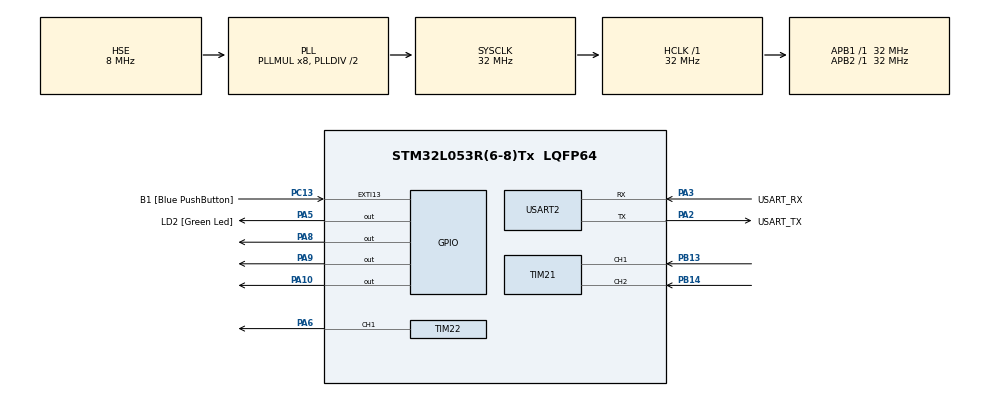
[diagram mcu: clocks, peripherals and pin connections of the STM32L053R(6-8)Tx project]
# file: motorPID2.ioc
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Mcu.Family=STM32L0
Mcu.Name=STM32L053R(6-8)Tx
Mcu.Package=LQFP64
NVIC.TIM2_IRQn=true\:0\:0\:false\:false\:true\:true\:true\:true
NVIC.USART2_IRQn=true\:0\:0\:false\:false\:true\:true\:true\:true
PA10.Signal=GPIO_Output
PA13.GPIO_Label=TMS
PA13.Mode=Serial_Wire
PA13.Signal=SYS_SWDIO
PA14.GPIO_Label=TCK
PA14.Mode=Serial_Wire
PA14.Signal=SYS_SWCLK
PA2.GPIO_Label=USART_TX
PA2.Mode=Asynchronous
PA2.Signal=USART2_TX
PA3.GPIO_Label=USART_RX
PA3.Mode=Asynchronous
PA3.Signal=USART2_RX
PA5.GPIO_Label=LD2 [Green Led]
PA5.Signal=GPIO_Output
PA6.Signal=S_TIM22_CH1
PA8.Signal=GPIO_Output
PA9.Signal=GPIO_Output
PB13.Signal=S_TIM21_CH1
PB14.Signal=S_TIM21_CH2
PC13.GPIO_Label=B1 [Blue PushButton]
PC13.GPIO_ModeDefaultEXTI=GPIO_MODE_IT_FALLING
PC13.Signal=GPXTI13
PC14-OSC32_IN.Mode=LSE-External-Oscillator
PC14-OSC32_IN.Signal=RCC_OSC32_IN
PC15-OSC32_OUT.Mode=LSE-External-Oscillator
PC15-OSC32_OUT.Signal=RCC_OSC32_OUT
PH0-OSC_IN.Mode=HSE-External-Clock-Source
PH0-OSC_IN.Signal=RCC_OSC_IN
PH1-OSC_OUT.Signal=RCC_OSC_OUT
ProjectManager.HeapSize=0x200
ProjectManager.StackSize=0x400
ProjectManager.TargetToolchain=STM32CubeIDE
RCC.AHBFreq_Value=32000000
RCC.APB1Freq_Value=32000000
RCC.APB1TimFreq_Value=32000000
RCC.APB2Freq_Value=32000000
RCC.APB2TimFreq_Value=32000000
RCC.HCLKFreq_Value=32000000
RCC.HSE_VALUE=8000000
RCC.HSI16_VALUE=16000000
RCC.HSI48_VALUE=48000000
RCC.HSI_VALUE=16000000
RCC.MSI_VALUE=2097000
RCC.PLLMUL=RCC_PLLMUL_8
RCC.PLLSourceVirtual=RCC_PLLSOURCE_HSE
RCC.SYSCLKFreq_VALUE=32000000
RCC.SYSCLKSource=RCC_SYSCLKSOURCE_PLLCLK
RCC.VCOOutputFreq_Value=64000000
SH.S_TIM21_CH1.0=TIM21_CH1,Encoder_Interface
SH.S_TIM21_CH2.0=TIM21_CH2,Encoder_Interface
SH.S_TIM22_CH1.0=TIM22_CH1,PWM Generation1 CH1
TIM2.Period=9
TIM2.Prescaler=3199
TIM21.AutoReloadPreload=TIM_AUTORELOAD_PRELOAD_ENABLE
TIM21.EncoderMode=TIM_ENCODERMODE_TI12
TIM21.IC1Filter=10
TIM22.Channel-PWM\ Generation1\ CH1=TIM_CHANNEL_1
TIM22.Period=799
USART2.VirtualMode-Asynchronous=VM_ASYNC
VP_TIM22_VS_ClockSourceINT.Mode=Internal
VP_TIM2_VS_ClockSourceINT.Mode=Internal
board=NUCLEO-L053R8

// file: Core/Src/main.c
/* USER CODE BEGIN Header */
/**
  ******************************************************************************
  * @file           : main.c
  * @brief          : Main program body
  ******************************************************************************
  * @attention
  *
  * Copyright (c) 2025 STMicroelectronics.
  * All rights reserved.
  *
  * This software is licensed under terms that can be found in the LICENSE file
  * in the root directory of this software component.
  * If no LICENSE file comes with this software, it is provided AS-IS.
  *
  ******************************************************************************
  */
/* USER CODE END Header */
#include "main.h"

/* USER CODE BEGIN Includes */
#include "myMain.h"
/* USER CODE END Includes */

TIM_HandleTypeDef htim2;
TIM_HandleTypeDef htim21;
TIM_HandleTypeDef htim22;

UART_HandleTypeDef huart2;

void SystemClock_Config(void);
static void MX_GPIO_Init(void);
static void MX_USART2_UART_Init(void);
static void MX_TIM2_Init(void);
static void MX_TIM21_Init(void);
static void MX_TIM22_Init(void);

int main(void)
{

  /* MCU Configuration--------------------------------------------------------*/

  /* Reset of all peripherals, Initializes the Flash interface and the Systick. */
  HAL_Init();

  /* Configure the system clock */
  SystemClock_Config();

  /* Initialize all configured peripherals */
  MX_GPIO_Init();
  MX_USART2_UART_Init();
  MX_TIM2_Init();
  MX_TIM21_Init();
  MX_TIM22_Init();

  /* Infinite loop */
  /* USER CODE BEGIN WHILE */

  myMain();

  while (1)
  {
    /* USER CODE END WHILE */

  }
}

void SystemClock_Config(void)
{
  RCC_OscInitTypeDef RCC_OscInitStruct = {0};
  RCC_ClkInitTypeDef RCC_ClkInitStruct = {0};
  RCC_PeriphCLKInitTypeDef PeriphClkInit = {0};

  /** Configure the main internal regulator output voltage
  */
  __HAL_PWR_VOLTAGESCALING_CONFIG(PWR_REGULATOR_VOLTAGE_SCALE1);

  /** Initializes the RCC Oscillators according to the specified parameters
  * in the RCC_OscInitTypeDef structure.
  */
  RCC_OscInitStruct.OscillatorType = RCC_OSCILLATORTYPE_HSE;
  RCC_OscInitStruct.HSEState = RCC_HSE_BYPASS;
  RCC_OscInitStruct.PLL.PLLState = RCC_PLL_ON;
  RCC_OscInitStruct.PLL.PLLSource = RCC_PLLSOURCE_HSE;
  RCC_OscInitStruct.PLL.PLLMUL = RCC_PLLMUL_8;
  RCC_OscInitStruct.PLL.PLLDIV = RCC_PLLDIV_2;
  if (HAL_RCC_OscConfig(&RCC_OscInitStruct) != HAL_OK)
  {
    Error_Handler();
  }

  /** Initializes the CPU, AHB and APB buses clocks
  */
  RCC_ClkInitStruct.ClockType = RCC_CLOCKTYPE_HCLK|RCC_CLOCKTYPE_SYSCLK
                              |RCC_CLOCKTYPE_PCLK1|RCC_CLOCKTYPE_PCLK2;
  RCC_ClkInitStruct.SYSCLKSource = RCC_SYSCLKSOURCE_PLLCLK;
  RCC_ClkInitStruct.AHBCLKDivider = RCC_SYSCLK_DIV1;
  RCC_ClkInitStruct.APB1CLKDivider = RCC_HCLK_DIV1;
  RCC_ClkInitStruct.APB2CLKDivider = RCC_HCLK_DIV1;

  if (HAL_RCC_ClockConfig(&RCC_ClkInitStruct, FLASH_LATENCY_1) != HAL_OK)
  {
    Error_Handler();
  }
  PeriphClkInit.PeriphClockSelection = RCC_PERIPHCLK_USART2;
  PeriphClkInit.Usart2ClockSelection = RCC_USART2CLKSOURCE_PCLK1;
  if (HAL_RCCEx_PeriphCLKConfig(&PeriphClkInit) != HAL_OK)
  {
    Error_Handler();
  }
}

static void MX_TIM2_Init(void)
{

  TIM_ClockConfigTypeDef sClockSourceConfig = {0};
  TIM_MasterConfigTypeDef sMasterConfig = {0};

  htim2.Instance = TIM2;
  htim2.Init.Prescaler = 3199;
  htim2.Init.CounterMode = TIM_COUNTERMODE_UP;
  htim2.Init.Period = 9;
  htim2.Init.ClockDivision = TIM_CLOCKDIVISION_DIV1;
  htim2.Init.AutoReloadPreload = TIM_AUTORELOAD_PRELOAD_DISABLE;
  if (HAL_TIM_Base_Init(&htim2) != HAL_OK)
  {
    Error_Handler();
  }
  sClockSourceConfig.ClockSource = TIM_CLOCKSOURCE_INTERNAL;
  if (HAL_TIM_ConfigClockSource(&htim2, &sClockSourceConfig) != HAL_OK)
  {
    Error_Handler();
  }
  sMasterConfig.MasterOutputTrigger = TIM_TRGO_RESET;
  sMasterConfig.MasterSlaveMode = TIM_MASTERSLAVEMODE_DISABLE;
  if (HAL_TIMEx_MasterConfigSynchronization(&htim2, &sMasterConfig) != HAL_OK)
  {
    Error_Handler();
  }

}

static void MX_TIM21_Init(void)
{

  TIM_Encoder_InitTypeDef sConfig = {0};
  TIM_MasterConfigTypeDef sMasterConfig = {0};

  htim21.Instance = TIM21;
  htim21.Init.Prescaler = 0;
  htim21.Init.CounterMode = TIM_COUNTERMODE_UP;
  htim21.Init.Period = 65535;
  htim21.Init.ClockDivision = TIM_CLOCKDIVISION_DIV1;
  htim21.Init.AutoReloadPreload = TIM_AUTORELOAD_PRELOAD_ENABLE;
  sConfig.EncoderMode = TIM_ENCODERMODE_TI12;
  sConfig.IC1Polarity = TIM_ICPOLARITY_RISING;
  sConfig.IC1Selection = TIM_ICSELECTION_DIRECTTI;
  sConfig.IC1Prescaler = TIM_ICPSC_DIV1;
  sConfig.IC1Filter = 10;
  sConfig.IC2Polarity = TIM_ICPOLARITY_RISING;
  sConfig.IC2Selection = TIM_ICSELECTION_DIRECTTI;
  sConfig.IC2Prescaler = TIM_ICPSC_DIV1;
  sConfig.IC2Filter = 0;
  if (HAL_TIM_Encoder_Init(&htim21, &sConfig) != HAL_OK)
  {
    Error_Handler();
  }
  sMasterConfig.MasterOutputTrigger = TIM_TRGO_RESET;
  sMasterConfig.MasterSlaveMode = TIM_MASTERSLAVEMODE_DISABLE;
  if (HAL_TIMEx_MasterConfigSynchronization(&htim21, &sMasterConfig) != HAL_OK)
  {
    Error_Handler();
  }

}

static void MX_TIM22_Init(void)
{

  TIM_ClockConfigTypeDef sClockSourceConfig = {0};
  TIM_MasterConfigTypeDef sMasterConfig = {0};
  TIM_OC_InitTypeDef sConfigOC = {0};

  htim22.Instance = TIM22;
  htim22.Init.Prescaler = 0;
  htim22.Init.CounterMode = TIM_COUNTERMODE_UP;
  htim22.Init.Period = 799;
  htim22.Init.ClockDivision = TIM_CLOCKDIVISION_DIV1;
  htim22.Init.AutoReloadPreload = TIM_AUTORELOAD_PRELOAD_DISABLE;
  if (HAL_TIM_Base_Init(&htim22) != HAL_OK)
  {
    Error_Handler();
  }
  sClockSourceConfig.ClockSource = TIM_CLOCKSOURCE_INTERNAL;
  if (HAL_TIM_ConfigClockSource(&htim22, &sClockSourceConfig) != HAL_OK)
  {
    Error_Handler();
  }
  if (HAL_TIM_PWM_Init(&htim22) != HAL_OK)
  {
    Error_Handler();
  }
  sMasterConfig.MasterOutputTrigger = TIM_TRGO_RESET;
  sMasterConfig.MasterSlaveMode = TIM_MASTERSLAVEMODE_DISABLE;
  if (HAL_TIMEx_MasterConfigSynchronization(&htim22, &sMasterConfig) != HAL_OK)
  {
    Error_Handler();
  }
  sConfigOC.OCMode = TIM_OCMODE_PWM1;
  sConfigOC.Pulse = 0;
  sConfigOC.OCPolarity = TIM_OCPOLARITY_HIGH;
  sConfigOC.OCFastMode = TIM_OCFAST_DISABLE;
  if (HAL_TIM_PWM_ConfigChannel(&htim22, &sConfigOC, TIM_CHANNEL_1) != HAL_OK)
  {
    Error_Handler();
  }
  HAL_TIM_MspPostInit(&htim22);

}

static void MX_USART2_UART_Init(void)
{

  huart2.Instance = USART2;
  huart2.Init.BaudRate = 115200;
  huart2.Init.WordLength = UART_WORDLENGTH_8B;
  huart2.Init.StopBits = UART_STOPBITS_1;
  huart2.Init.Parity = UART_PARITY_NONE;
  huart2.Init.Mode = UART_MODE_TX_RX;
  huart2.Init.HwFlowCtl = UART_HWCONTROL_NONE;
  huart2.Init.OverSampling = UART_OVERSAMPLING_16;
  huart2.Init.OneBitSampling = UART_ONE_BIT_SAMPLE_DISABLE;
  huart2.AdvancedInit.AdvFeatureInit = UART_ADVFEATURE_NO_INIT;
  if (HAL_UART_Init(&huart2) != HAL_OK)
  {
    Error_Handler();
  }

}

static void MX_GPIO_Init(void)
{
  GPIO_InitTypeDef GPIO_InitStruct = {0};

  /* GPIO Ports Clock Enable */
  __HAL_RCC_GPIOC_CLK_ENABLE();
  __HAL_RCC_GPIOH_CLK_ENABLE();
  __HAL_RCC_GPIOA_CLK_ENABLE();
  __HAL_RCC_GPIOB_CLK_ENABLE();

  /*Configure GPIO pin Output Level */
  HAL_GPIO_WritePin(GPIOA, LD2_Pin|GPIO_PIN_8|GPIO_PIN_9|GPIO_PIN_10, GPIO_PIN_RESET);

  /*Configure GPIO pin : B1_Pin */
  GPIO_InitStruct.Pin = B1_Pin;
  GPIO_InitStruct.Mode = GPIO_MODE_IT_FALLING;
  GPIO_InitStruct.Pull = GPIO_NOPULL;
  HAL_GPIO_Init(B1_GPIO_Port, &GPIO_InitStruct);

  /*Configure GPIO pins : LD2_Pin PA8 PA9 PA10 */
  GPIO_InitStruct.Pin = LD2_Pin|GPIO_PIN_8|GPIO_PIN_9|GPIO_PIN_10;
  GPIO_InitStruct.Mode = GPIO_MODE_OUTPUT_PP;
  GPIO_InitStruct.Pull = GPIO_NOPULL;
  GPIO_InitStruct.Speed = GPIO_SPEED_FREQ_LOW;
  HAL_GPIO_Init(GPIOA, &GPIO_InitStruct);

}

void Error_Handler(void)
{
  __disable_irq();
  while (1)
  {
  }
}
